AUTOSAR XML
package /AccSwcs
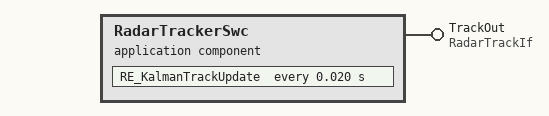
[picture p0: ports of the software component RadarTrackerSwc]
  application sw component type RadarTrackerSwc
    provide port TrackOut: provided-interface=RadarTrackIf
    behavior RadarTracker_IB
      runnable RE_KalmanTrackUpdate: execution-time-wcet=0.0045
      timing event TE_Radar_20ms: start-on-event=RE_KalmanTrackUpdate, period=0.020
